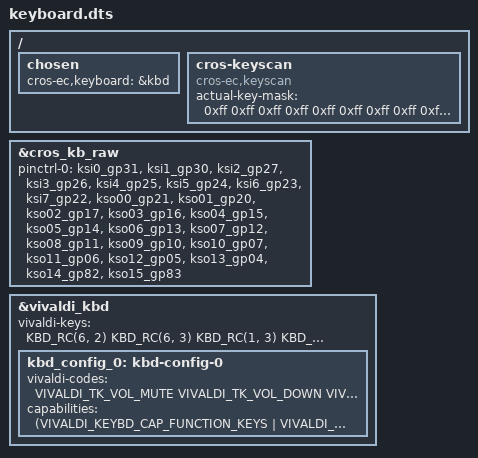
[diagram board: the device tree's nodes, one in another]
/* Copyright 2022 The ChromiumOS Authors
 * Use of this source code is governed by a BSD-style license that can be
 * found in the LICENSE file.
 */
&cros_kb_raw {
	status = "okay";
	/* No KSO2 (it's inverted and implemented by GPIO) */
	pinctrl-0 = <
		&ksi0_gp31
		&ksi1_gp30
		&ksi2_gp27
		&ksi3_gp26
		&ksi4_gp25
		&ksi5_gp24
		&ksi6_gp23
		&ksi7_gp22
		&kso00_gp21
		&kso01_gp20
		&kso02_gp17
		&kso03_gp16
		&kso04_gp15
		&kso05_gp14
		&kso06_gp13
		&kso07_gp12
		&kso08_gp11
		&kso09_gp10
		&kso10_gp07
		&kso11_gp06
		&kso12_gp05
		&kso13_gp04
		&kso14_gp82
		&kso15_gp83
	>;
	pinctrl-names = "default";
};

/ {
	chosen {
		cros-ec,keyboard = &kbd;
	};

	cros-keyscan {
		compatible = "cros-ec,keyscan";

		/* TODO: Use actual values */
		actual-key-mask = <
			0xff  /* C0 */
			0xff  /* C1 */
			0xff  /* C2 */
			0xff  /* C3 */
			0xff  /* C4 */
			0xff  /* C5 */
			0xff  /* C6 */
			0xff  /* C7 */
			0xff  /* C8 */
			0xff  /* C9 */
			0xff  /* C10 */
			0xff  /* C11 */
			0xff  /* C12 */
			0xff  /* C13 */
			0xff  /* C14 */
			0xff  /* C15 */
			>;
	};
};

&vivaldi_kbd {
	vivaldi-keys = <
		KBD_RC(6, 2)   /* T1 */
		KBD_RC(6, 3)   /* T2 */
		KBD_RC(1, 3)   /* T3 */
		KBD_RC(3, 3)   /* T4 */
		KBD_RC(7, 0)   /* T5 */
		KBD_RC(3, 6)   /* T6 */
		KBD_RC(1, 7)   /* T7 */
		KBD_RC(6, 7)   /* T8 */
		KBD_RC(6, 10)  /* T9 */
		KBD_RC(7, 10)  /* T10 */
		KBD_RC(3, 10)  /* T11 */
		KBD_RC(5, 10)  /* T12 */
	>;

	kbd_config_0: kbd-config-0 {
		vivaldi-codes = <
			VIVALDI_TK_VOL_MUTE           /* T1 */
			VIVALDI_TK_VOL_DOWN           /* T2 */
			VIVALDI_TK_VOL_UP             /* T3 */
			VIVALDI_TK_PLAY_PAUSE         /* T4 */
			VIVALDI_TK_FULLSCREEN         /* T5* */
			VIVALDI_TK_SNAPSHOT           /* T6* */
			VIVALDI_TK_BACK               /* T7* */
			VIVALDI_TK_REFRESH            /* T8* */
			VIVALDI_TK_BRIGHTNESS_DOWN    /* T9 */
			VIVALDI_TK_BRIGHTNESS_UP      /* T10 */
			VIVALDI_TK_DONOTDISTURB       /* T11* */
			VIVALDI_TK_OVERVIEW           /* T12* */
		>;
		capabilities = <(VIVALDI_KEYBD_CAP_FUNCTION_KEYS |
				VIVALDI_KEYBD_CAP_SCRNLOCK_KEY |
				VIVALDI_KEYBD_CAP_ASSISTANT_KEY)>;
	};
};
